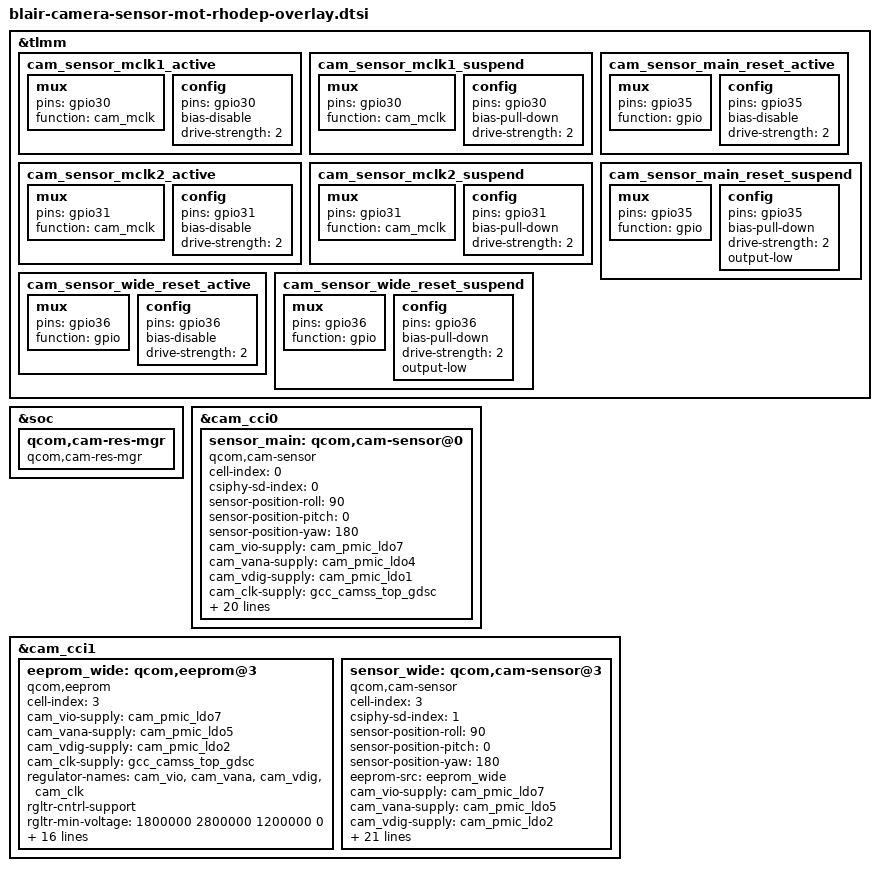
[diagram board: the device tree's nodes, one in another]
#include <dt-bindings/clock/qcom,gcc-blair.h>

&tlmm {
	cam_sensor_mclk1_active: cam_sensor_mclk1_active {
		mux {
			pins = "gpio30";
			function = "cam_mclk";
		};

		config {
			pins = "gpio30";
			bias-disable; /* No PULL */
			drive-strength = <2>;
		};
	};

	cam_sensor_mclk1_suspend: cam_sensor_mclk1_suspend {
		mux {
			pins = "gpio30";
			function = "cam_mclk";
		};

		config {
			pins = "gpio30";
			bias-pull-down; /* PULL DOWN */
			drive-strength = <2>;
		};
	};

	cam_sensor_mclk2_active: cam_sensor_mclk2_active {
		mux {
			pins = "gpio31";
			function = "cam_mclk";
		};

		config {
			pins = "gpio31";
			bias-disable; /* No PULL */
			drive-strength = <2>;
		};
	};

	cam_sensor_mclk2_suspend: cam_sensor_mclk2_suspend {
		mux {
			pins = "gpio31";
			function = "cam_mclk";
		};

		config {
			pins = "gpio31";
			bias-pull-down; /* PULL DOWN */
			drive-strength = <2>;
		};
	};

	cam_sensor_main_reset_active: cam_sensor_main_reset_active {
		mux {
			pins = "gpio35";
			function = "gpio";
		};

		config {
			pins = "gpio35";
			bias-disable; /* No PULL */
			drive-strength = <2>; /* 2 MA */
		};
	};

	cam_sensor_main_reset_suspend: cam_sensor_main_reset_suspend {
		mux {
			pins = "gpio35";
			function = "gpio";
		};

		config {
			pins = "gpio35";
			bias-pull-down; /* PULL DOWN */
			drive-strength = <2>; /* 2 MA */
			output-low;
		};
	};

	cam_sensor_wide_reset_active: cam_sensor_wide_reset_active {
		mux {
			pins = "gpio36";
			function = "gpio";
		};

		config {
			pins = "gpio36";
			bias-disable; /* No PULL */
			drive-strength = <2>; /* 2 MA */
		};
	};

	cam_sensor_wide_reset_suspend: cam_sensor_wide_reset_suspend {
		mux {
			pins = "gpio36";
			function = "gpio";
		};

		config {
			pins = "gpio36";
			bias-pull-down; /* PULL DOWN */
			drive-strength = <2>; /* 2 MA */
			output-low;
		};
	};

};

&soc {
	qcom,cam-res-mgr {
		compatible = "qcom,cam-res-mgr";
		status = "ok";
	};
};

&cam_cci0 {
	sensor_main: qcom,cam-sensor@0 {
		cell-index = <0>;
		compatible = "qcom,cam-sensor";
		csiphy-sd-index = <0>;
		sensor-position-roll = <90>;
		sensor-position-pitch = <0>;
		sensor-position-yaw = <180>;
		cam_vio-supply = <&cam_pmic_ldo7>;
		cam_vana-supply = <&cam_pmic_ldo4>;
		cam_vdig-supply = <&cam_pmic_ldo1>;
		cam_clk-supply = <&gcc_camss_top_gdsc>;
		regulator-names = "cam_vio", "cam_vana", "cam_vdig",
			"cam_clk";
		rgltr-cntrl-support;
		rgltr-min-voltage = <1800000 2800000 1050000 0>;
		rgltr-max-voltage = <1800000 2800000 1050000 0>;
		rgltr-load-current = <120000 80000 1200000 0>;
		gpio-no-mux = <0>;
		pinctrl-names = "cam_default", "cam_suspend";
		pinctrl-0 = <&cam_sensor_mclk1_active
				&cam_sensor_main_reset_active>;
		pinctrl-1 = <&cam_sensor_mclk1_suspend
				&cam_sensor_main_reset_suspend>;
		gpios = <&tlmm 30 0>,
			<&tlmm 35 0>;
		gpio-reset = <1>;
		gpio-req-tbl-num = <0 1>;
		gpio-req-tbl-flags = <1 0>;
		gpio-req-tbl-label = "CAMIF_MCLK1",
					"CAM_RM_RST";
		cci-master = <1>;
		status = "ok";
		clocks = <&gcc GCC_CAMSS_MCLK1_CLK>;
		clock-names = "cam_clk";
		clock-cntl-level = "turbo";
		clock-rates = <24000000>;
	};
};

&cam_cci1 {
	eeprom_wide: qcom,eeprom@3 {
		cell-index = <3>;
		compatible = "qcom,eeprom";
		cam_vio-supply = <&cam_pmic_ldo7>;
		cam_vana-supply = <&cam_pmic_ldo5>;
		cam_vdig-supply = <&cam_pmic_ldo2>;
		cam_clk-supply = <&gcc_camss_top_gdsc>;
		regulator-names = "cam_vio", "cam_vana", "cam_vdig",
			"cam_clk";
		rgltr-cntrl-support;
		rgltr-min-voltage = <1800000 2800000 1200000 0>;
		rgltr-max-voltage = <1800000 2800000 1200000 0>;
		rgltr-load-current = <120000 80000 1200000 0>;
		gpio-no-mux = <0>;
		pinctrl-names = "cam_default", "cam_suspend";
		pinctrl-0 = <&cam_sensor_mclk2_active
				&cam_sensor_wide_reset_active>;
		pinctrl-1 = <&cam_sensor_mclk2_suspend
				&cam_sensor_wide_reset_suspend>;
		gpios = <&tlmm 31 0>,
			<&tlmm 36 0>;
		gpio-reset = <1>;
		gpio-req-tbl-num = <0 1>;
		gpio-req-tbl-flags = <1 0>;
		gpio-req-tbl-label = "CAMIF_MCLK2",
					"CAM_RW_RST";
		cci-master = <0>;
		status = "ok";
		clocks = <&gcc GCC_CAMSS_MCLK2_CLK>;
		clock-names = "cam_clk";
		clock-cntl-level = "turbo";
		clock-rates = <24000000>;
	};
	sensor_wide: qcom,cam-sensor@3 {
		cell-index = <3>;
		compatible = "qcom,cam-sensor";
		csiphy-sd-index = <1>;
		sensor-position-roll = <90>;
		sensor-position-pitch = <0>;
		sensor-position-yaw = <180>;
		eeprom-src = <&eeprom_wide>;
		cam_vio-supply = <&cam_pmic_ldo7>;
		cam_vana-supply = <&cam_pmic_ldo5>;
		cam_vdig-supply = <&cam_pmic_ldo2>;
		cam_clk-supply = <&gcc_camss_top_gdsc>;
		regulator-names = "cam_vio", "cam_vana", "cam_vdig",
			"cam_clk";
		rgltr-cntrl-support;
		rgltr-min-voltage = <1800000 2800000 1200000 0>;
		rgltr-max-voltage = <1800000 2800000 1200000 0>;
		rgltr-load-current = <120000 80000 1200000 0>;
		gpio-no-mux = <0>;
		pinctrl-names = "cam_default", "cam_suspend";
		pinctrl-0 = <&cam_sensor_mclk2_active
				&cam_sensor_wide_reset_active>;
		pinctrl-1 = <&cam_sensor_mclk2_suspend
				&cam_sensor_wide_reset_suspend>;
		gpios = <&tlmm 31 0>,
			<&tlmm 36 0>;
		gpio-reset = <1>;
		gpio-req-tbl-num = <0 1>;
		gpio-req-tbl-flags = <1 0>;
		gpio-req-tbl-label = "CAMIF_MCLK2",
					"CAM_RW_RST";
		cci-master = <0>;
		status = "ok";
		clocks = <&gcc GCC_CAMSS_MCLK2_CLK>;
		clock-names = "cam_clk";
		clock-cntl-level = "turbo";
		clock-rates = <24000000>;
	};
};
